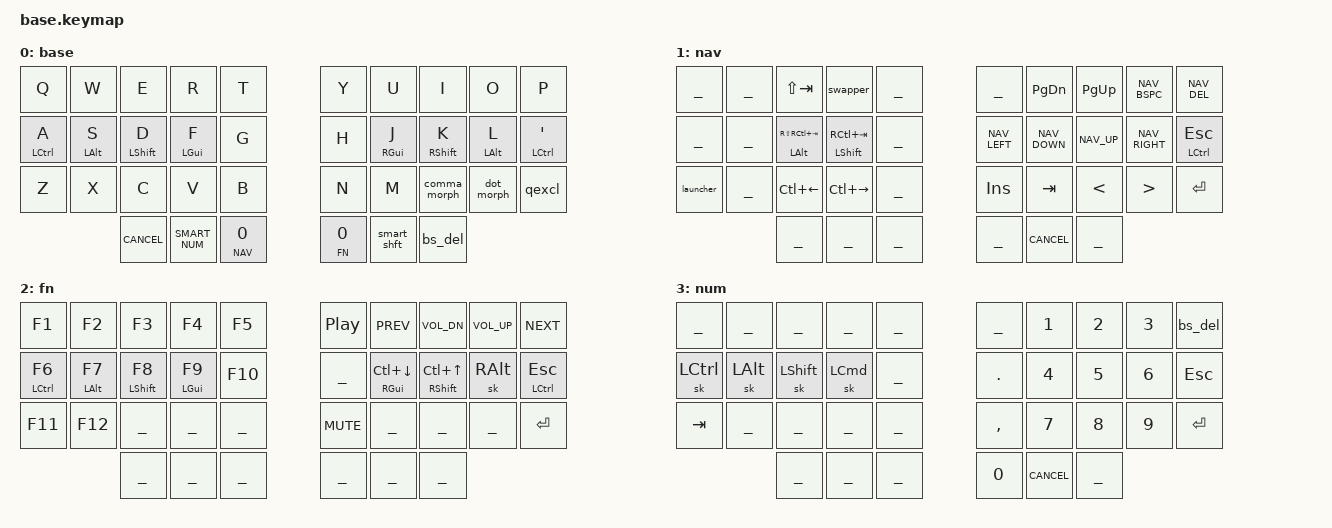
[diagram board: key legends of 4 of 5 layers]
#include <behaviors.dtsi>
#include <dt-bindings/zmk/keys.h>

#include "globals.h"
#include "layers.h"

#include "behaviors.dtsi"
#include "combos.dtsi"  // requires layer aliases

// misc aliases
#define CANCEL      &kp K_CANCEL             // cancel caps-word, num-word

// macOS aliases
#define DSK_PREV    &kp LC(LEFT)             // previous desktop
#define DSK_NEXT    &kp LC(RIGHT)            // next     desktop
#define DSK_ALL     &hmr RSHFT LC(UP)        // show all windows
#define DSK_APP     &hmr RGUI LC(DOWN)       // show app windows

#define TAB_RIGHT   &hml LSHFT RC(TAB)       // Next Tab
#define TAB_LEFT    &hml LALT RS(RC(TAB))    // Prev Tab

#define VOL_DOWN    &kp C_VOL_DN

/* Keymap */

ZMK_CONDITIONAL_LAYER(FN NAV, SYS)  // FN + NAV --> SYS

ZMK_LAYER(base,
// ╭─────────────┬─────────────┬─────────────┬─────────────┬─────────────╮  ╭─────────────┬─────────────┬─────────────┬─────────────┬─────────────╮
     &kp Q         &kp W         &kp E         &kp R         &kp T            &kp Y         &kp U         &kp I         &kp O         &kp P
// ├─────────────┼─────────────┼─────────────┼─────────────┼─────────────┤  ├─────────────┼─────────────┼─────────────┼─────────────┼─────────────┤
     &hml LCTRL A   &hml LALT S   &hml LSHFT D  &hml LGUI F  &kp G            &kp H         &hmr RGUI J   &hmr RSHFT K  &hmr LALT L   &hmr LCTRL SQT
// ├─────────────┼─────────────┼─────────────┼─────────────┼─────────────┤  ├─────────────┼─────────────┼─────────────┼─────────────┼─────────────┤
     &kp Z         &kp X         &kp C         &kp V         &kp B            &kp N         &kp M         &comma_morph  &dot_morph    &qexcl
// ╰─────────────┴─────────────┼─────────────┼─────────────┼─────────────┤  ├─────────────┼─────────────┼─────────────┴─────────────┴─────────────╯
                                 CANCEL        SMART_NUM     &lt_spc NAV 0    &lt_spc FN 0  &smart_shft   &bs_del
//                             ╰─────────────┴─────────────┴─────────────╯  ╰─────────────┴─────────────┴─────────────╯
)

ZMK_LAYER(nav,
// ╭─────────────┬─────────────┬─────────────┬─────────────┬─────────────╮  ╭─────────────┬─────────────┬─────────────┬─────────────┬─────────────╮
     ___           ___           &kp LS(TAB)   &swapper      ___              ___           &kp PG_DN     &kp PG_UP     NAV_BSPC      NAV_DEL
// ├─────────────┼─────────────┼─────────────┼─────────────┼─────────────┤  ├─────────────┼─────────────┼─────────────┼─────────────┼─────────────┤
     ___           ___           TAB_LEFT      TAB_RIGHT     ___              NAV_LEFT      NAV_DOWN      NAV_UP        NAV_RIGHT     &hmr LCTRL ESC
// ├─────────────┼─────────────┼─────────────┼─────────────┼─────────────┤  ├─────────────┼─────────────┼─────────────┼─────────────┼─────────────┤
     &launcher     ___           DSK_PREV      DSK_NEXT      ___              &kp INS       &kp TAB       &kp LT        &kp GT        &kp RET
// ╰─────────────┴─────────────┼─────────────┼─────────────┼─────────────┤  ├─────────────┼─────────────┼─────────────┴───────────────────────────╯
                                 ___           ___           ___              ___           CANCEL        ___
//                             ╰─────────────┴─────────────┴─────────────╯  ╰─────────────┴─────────────┴─────────────╯
)

ZMK_LAYER(fn,
// ╭─────────────┬─────────────┬─────────────┬─────────────┬─────────────╮  ╭─────────────┬─────────────┬─────────────┬─────────────┬─────────────╮
     &kp F1        &kp F2        &kp F3        &kp F4        &kp F5           &kp C_PP      &kp C_PREV    VOL_DOWN      &kp C_VOL_UP  &kp C_NEXT
// ├─────────────┼─────────────┼─────────────┼─────────────┼─────────────┤  ├─────────────┼─────────────┼─────────────┼─────────────┼─────────────┤
     &hml LCTRL F6 &hml LALT F7  &hml LSHFT F8 &hml LGUI F9  &kp F10          ___           DSK_APP       DSK_ALL       &sk RALT      &hmr LCTRL ESC
// ├─────────────┼─────────────┼─────────────┼─────────────┼─────────────┤  ├─────────────┼─────────────┼─────────────┼─────────────┼─────────────┤
     &kp F11       &kp F12       ___           ___           ___              &kp C_MUTE    ___           ___           ___           &kp RET
// ╰─────────────┴─────────────┼─────────────┼─────────────┼─────────────┤  ├─────────────┼─────────────┼─────────────┴───────────────────────────╯
                                 ___           ___           ___              ___           ___           ___
//                             ╰─────────────┴─────────────┴─────────────╯  ╰─────────────┴─────────────┴─────────────╯
)

ZMK_LAYER(num,
// ╭─────────────┬─────────────┬─────────────┬─────────────┬─────────────╮  ╭─────────────┬─────────────┬─────────────┬─────────────┬─────────────╮
     ___           ___           ___           ___           ___              ___           &kp N1        &kp N2        &kp N3        &bs_del
// ├─────────────┼─────────────┼─────────────┼─────────────┼─────────────┤  ├─────────────┼─────────────┼─────────────┼─────────────┼─────────────┤
     &sk LCTRL     &sk LALT      &sk LSHIFT    &sk LCMD      ___              &kp DOT       &kp N4        &kp N5        &kp N6        &kp ESC
// ├─────────────┼─────────────┼─────────────┼─────────────┼─────────────┤  ├─────────────┼─────────────┼─────────────┼─────────────┼─────────────┤
     &kp TAB       ___           ___           ___           ___              &kp COMMA     &kp N7        &kp N8        &kp N9        &kp RET
// ╰─────────────┴─────────────┼─────────────┼─────────────┼─────────────┤  ├─────────────┼─────────────┼─────────────┴───────────────────────────╯
                                 ___           ___           ___              &kp N0        CANCEL        ___
//                             ╰─────────────┴─────────────┴─────────────╯  ╰─────────────┴─────────────┴─────────────╯
)

ZMK_LAYER(sys,
// ╭─────────────┬─────────────┬─────────────┬─────────────┬─────────────╮  ╭─────────────┬─────────────┬─────────────┬─────────────┬─────────────╮
                                _BT_SEL_KEYS_                                 ___           ___           ___           ___           ___
// ├─────────────┼─────────────┼─────────────┼─────────────┼─────────────┤  ├─────────────┼─────────────┼─────────────┼─────────────┼─────────────┤
     ___           ___           ___           ___           &bootloader      &bootloader   &bums         &bude         ___           ___
// ├─────────────┼─────────────┼─────────────┼─────────────┼─────────────┤  ├─────────────┼─────────────┼─────────────┼─────────────┼─────────────┤
     ___           ___           ___           ___           &sys_reset       &sys_reset    &foo          &bar          ___           ___
// ╰─────────────┴─────────────┼─────────────┼─────────────┼─────────────┤  ├─────────────┼─────────────┼─────────────┴───────────────────────────╯
                                 ___           ___           ___              ___           ___           ___
//                             ╰─────────────┴─────────────┴─────────────╯  ╰─────────────┴─────────────┴─────────────╯
)

/* vim: set ft=c tw=174: */
